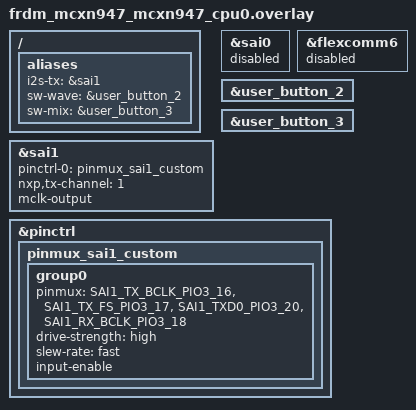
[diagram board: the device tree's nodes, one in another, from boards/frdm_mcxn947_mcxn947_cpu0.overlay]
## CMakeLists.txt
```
# Copyright (c) 2026 Jan-Willem Smaal <usenet@gispen.org>
# SPDX-License-Identifier: Apache-2.0

cmake_minimum_required(VERSION 3.20.0)
set(KCONFIG_ROOT ${CMAKE_CURRENT_SOURCE_DIR}/Kconfig)
find_package(Zephyr REQUIRED HINTS $ENV{ZEPHYR_BASE})
project(mcp4725_sine)

target_sources(app PRIVATE 
    src/main.c 
    src/generators.c
    src/effects.c
    src/mixer.c
)
```

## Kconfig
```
# Copyright (c) 2026 Jan-Willem Smaal <usenet@gispen.org>
# SPDX-License-Identifier: Apache-2.0

menu "Waveform Generator Options"

config WAVEFORM_FREQUENCY
	int "Waveform frequency (Hz)"
	default 1000
	help
	  The target frequency of the generated waveform in Hz.

config AUDIO_SAMPLE_RATE
	int "Sample Rate (Hz)"
	default 192000
	help
	  How many times per second the audio value is updated. (Recommended: 192000 for low aliasing)

config AUDIO_BIT_WIDTH
	int "Sample Bit Width"
	default 16
	range 16 32
	help
	  The bit width of each audio sample (16 or 32).

endmenu

source "Kconfig.zephyr"
```

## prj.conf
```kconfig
CONFIG_GPIO=y
CONFIG_I2S=y
CONFIG_CMSIS_DSP=y
CONFIG_CMSIS_DSP_FASTMATH=y
CONFIG_CMSIS_DSP_BASICMATH=y
CONFIG_I2S_TX_BLOCK_COUNT=8
CONFIG_LOG=y
```

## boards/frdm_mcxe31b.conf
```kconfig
# MCX E-series does not use the i.MX RT style Audio PLL configuration in the SAI driver.
# Disabling this prevents a compilation error in i2s_mcux_sai.c.
CONFIG_I2S_HAS_PLL_SETTING=n
```

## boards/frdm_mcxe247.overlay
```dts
/*
 * FRDM-MCXE247 SAI/I2S Configuration
 * Physical Mapping (Header J1 Inner Row):
 * - Pin 1:  Bit Clock (BCK)   -> PTB8
 * - Pin 5:  Data Out (DIN)    -> PTB9
 * - Pin 11: Frame Sync (LRCK) -> PTE2
 */

&sai1 {
	status = "okay";
	pinctrl-0 = <&pinmux_sai1>;
	pinctrl-names = "default";
	nxp,tx-channel = <1>; /* Bitmask: 1 = Channel 0 (TXD0) */
};

/ {
	aliases {
		i2s-tx = &sai1;
		sw-wave = &user_button_2; /* SW2 */
		sw-mix = &user_button_3;  /* SW3 */
	};
};

&pinctrl {
	pinmux_sai1: pinmux_sai1 {
		group0 {
			pinmux = <SAI1_BCLK_PTB8>,
				 <SAI1_SYNC_PTE2>,
				 <SAI1_D0_PTB9>;
			drive-strength = "high";
			slew-rate = "fast";
			input-enable;
		};
	};
};
```

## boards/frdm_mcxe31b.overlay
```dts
/*
 * FRDM-MCXE31B SAI/I2S Configuration
 * Physical Mapping (Header J1 Inner Row):
 * - Pin 1:  Bit Clock (BCK)   -> PTC12
 * - Pin 5:  Data Out (DIN)    -> PTB2
 * - Pin 11: Frame Sync (LRCK) -> PTC13
 */

&sai_0 {
	status = "okay";
	compatible = "nxp,mcux-i2s";
	pinctrl-0 = <&pinmux_sai0>;
	pinctrl-names = "default";
	#address-cells = <1>;
	#size-cells = <0>;
	#pinmux-cells = <2>;
	clocks = <&mc_cgm 0x2a00>; /* MCUX_SAI0_CLK */
	dmas = <&edma 0 55>, <&edma 0 56>; /* RX, TX */
	dma-names = "rx", "tx";
	nxp,rx-dma-channel = <0>;
	nxp,tx-dma-channel = <1>;
	nxp,tx-channel = <1>; /* Bitmask: 1 = Channel 0 (TXD0) */
};

/ {
	aliases {
		i2s-tx = &sai_0;
		sw-wave = &user_button; /* SW3 on E31B */
	};
};

&pinctrl {
	pinmux_sai0: pinmux_sai0 {
		group0 {
			pinmux = <PTC12_SAI0_BCLK_O>,
				 <PTC13_SAI0_SYNC_O>,
				 <PTB2_SAI0_D0_O>;
			slew-rate = "fastest";
			input-enable;
		};
	};
};
```

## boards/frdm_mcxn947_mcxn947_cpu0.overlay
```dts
&sai1 {
	status = "okay";
	pinctrl-0 = <&pinmux_sai1_custom>;
	pinctrl-names = "default";
	nxp,tx-channel = <1>; /* Bitmask: 1 = Channel 0 (TXD0) */
	mclk-output;          /* MANDATORY for MCXN947 to enable internal clock generator */
};

&sai0 {
	status = "disabled";
};

&flexcomm6 {
	status = "disabled";
};

/ {
	aliases {
		i2s-tx = &sai1;
		sw-wave = &user_button_2; /* SW2 */
		sw-mix = &user_button_3;  /* SW3 */
	};
};

&user_button_2 {
	status = "okay";
};

&user_button_3 {
	status = "okay";
};

&pinctrl {
	pinmux_sai1_custom: pinmux_sai1_custom {
		group0 {
			pinmux = <SAI1_TX_BCLK_PIO3_16>,   /* J1 Pin 1  - Bit Clock */
				 <SAI1_TX_FS_PIO3_17>,     /* J1 Pin 3  - Frame Sync (LRCK) */
				 <SAI1_TXD0_PIO3_20>,      /* J1 Pin 5  - Data Out */
				 <SAI1_RX_BCLK_PIO3_18>;   /* J1 Pin 9  - Bit Clock (Swapped) */
			/* NOTE: PIO1_21 (MCLK) removed to reduce EMI near data lines */
			drive-strength = "high";
			slew-rate = "fast";
			input-enable;
		};
	};
};
```

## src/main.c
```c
/*
 * Copyright 2026 Jan-Willem Smaal <usenet@gispen.org>
 * SPDX-License-Identifier: Apache-2.0
 */

/**
 * @file main.c
 * @brief Multi-Threaded Waveform Generator for PCM5102A (I2S)
 * @author Jan-Willem Smaal <usenet@gispen.org>
 */

#include <zephyr/kernel.h>
#include <zephyr/drivers/i2s.h>
#include <zephyr/drivers/gpio.h>
#include <zephyr/logging/log.h>
#include <arm_math.h>

#include "generators.h"
#include "effects.h"
#include "mixer.h"

LOG_MODULE_REGISTER(waveform_gen, CONFIG_LOG_DEFAULT_LEVEL);

/* --- Configuration --- */
#define I2S_NODE DT_ALIAS(i2s_tx)
#define SW_WAVE_NODE DT_ALIAS(sw_wave)
#define SW_MIX_NODE  DT_ALIAS(sw_mix)

#define SAMPLE_RATE CONFIG_AUDIO_SAMPLE_RATE
#define SAMPLE_BIT_WIDTH CONFIG_AUDIO_BIT_WIDTH
#define CHANNELS 2
#define SAMPLES_PER_BLOCK 128
#define BLOCK_SIZE (SAMPLES_PER_BLOCK * CHANNELS * sizeof(int16_t))
#define BLOCK_COUNT 16

/* Constants for Phase Math */
#define NCO_RANGE_F 4294967296.0f

/* Attenuation factor: ~0.15 (approx -16dB reduction to target -10dBV) */
#define ATTENUATION_FACTOR 4915

/* Audio Thread Settings */
#define AUDIO_STACK_SIZE 2048
#define AUDIO_PRIORITY -2

/* Slab for TX */
K_MEM_SLAB_DEFINE(audio_slab, BLOCK_SIZE, BLOCK_COUNT, 32);
/* Dummy slab for RX */
K_MEM_SLAB_DEFINE(rx_slab, BLOCK_SIZE, 4, 32); 

enum effect_mode {
	EFFECT_BYPASS = 0,
	EFFECT_BITCRUSH,
	EFFECT_BITBEEF,
	EFFECT_COUNT
};

struct synth_state {
	struct k_mutex lock;
	enum waveform_type current_waveform;
	uint32_t frequency;
	uint32_t phase_inc;
	bool mode_changed;
	bool mix_mode;
	enum effect_mode effect;
};

static struct synth_state g_state = {
	.current_waveform = WAVE_SINE,
	.frequency = 440,
	.mode_changed = true,
	.mix_mode = false,
	.effect = EFFECT_BYPASS,
};

static const struct device *const i2s_dev = DEVICE_DT_GET(I2S_NODE);

/* --- Helpers --- */

static void update_phase_inc(struct synth_state *state)
{
	/* Constant for 32-bit phase accumulator: (2^32 / SAMPLE_RATE) */
	const float phase_inc_factor = NCO_RANGE_F / SAMPLE_RATE;
	state->phase_inc = (uint32_t)(state->frequency * phase_inc_factor);
}

static void interleave_stereo(q15_t *mono, int16_t *stereo, uint32_t samples)
{
	for (uint32_t i = 0; i < samples; i++) {
		int16_t val = mono[i];
		stereo[i * 2] = val;     /* Left */
		stereo[i * 2 + 1] = val; /* Right */
	}
}

/* --- Threads --- */

void audio_thread_fn(void *p1, void *p2, void *p3)
{
	struct synth_state *state = (struct synth_state *)p1;
	ARG_UNUSED(p2); ARG_UNUSED(p3);
	uint32_t master_phase = 0;
	q15_t mono_buffer[SAMPLES_PER_BLOCK];
	q15_t mono_buffer2[SAMPLES_PER_BLOCK];
	void *mem_block;
	bool started = false;
	int ret;

	LOG_INF("Audio Engine Thread Started (Priority %d)", AUDIO_PRIORITY);

	while (1) {
		enum waveform_type mode;
		uint32_t phase_inc;
		bool mix_active;
		enum effect_mode effect;
		uint32_t local_phase;

		/* Synchronize control parameters */
		k_mutex_lock(&state->lock, K_FOREVER);
		mode = state->current_waveform;
		phase_inc = state->phase_inc;
		mix_active = state->mix_mode;
		effect = state->effect;

		if (state->mode_changed) {
			const char *fx_name = "BYPASS";

			if (effect == EFFECT_BITCRUSH) {
				fx_name = "BITCRUSH (4-bit)";
			} else if (effect == EFFECT_BITBEEF) {
				fx_name = "BITBEEF (0xBEEF)";
			}

			if (mix_active) {
				LOG_INF("Audio Mode -> %s (Mixed) [Effect: %s]", 
					get_waveform_name(mode), fx_name);
			} else {
				LOG_INF("Audio Mode -> %s [Effect: %s]", 
					get_waveform_name(mode), fx_name);
			}
			state->mode_changed = false;
		}
		k_mutex_unlock(&state->lock);

		/* DSP Pipeline */
		local_phase = master_phase;
		generate_waveform_batch(mode, mono_buffer, SAMPLES_PER_BLOCK, &local_phase, phase_inc);

		if (mix_active) {
			uint32_t harmonic_phase = master_phase * 2;
			uint32_t harmonic_inc = phase_inc * 2;
			uint32_t dummy_phase = harmonic_phase;
			
			generate_waveform_batch(mode, mono_buffer2, SAMPLES_PER_BLOCK, &dummy_phase, harmonic_inc);
			mixer_combine(mono_buffer, mono_buffer2, SAMPLES_PER_BLOCK);
		}

		switch (effect) {
		case EFFECT_BITCRUSH:
			effect_bitcrush(mono_buffer, SAMPLES_PER_BLOCK, 4);
			break;
		case EFFECT_BITBEEF:
			effect_bitbeef(mono_buffer, SAMPLES_PER_BLOCK);
			break;
		default:
			break;
		}

		effect_attenuate(mono_buffer, SAMPLES_PER_BLOCK, ATTENUATION_FACTOR);
		master_phase = local_phase;

		/* Output Processing */
		ret = k_mem_slab_alloc(&audio_slab, &mem_block, K_FOREVER);
		if (ret < 0) {
			continue;
		}

		interleave_stereo(mono_buffer, (int16_t *)mem_block, SAMPLES_PER_BLOCK);

		/* 
		 * Real-time audio: If the queue is full (-EAGAIN), do not block or retry.
		 * The time window has passed, so we simply drop this block and move on.
		 */
		ret = i2s_write(i2s_dev, mem_block, BLOCK_SIZE);
		if (ret < 0) {
			k_mem_slab_free(&audio_slab, mem_block);
			if (ret != -EAGAIN) {
				LOG_ERR("I2S write failed: %d", ret);
				return;
			}
			/* If EAGAIN, we dropped the block. Proceed to next loop immediately. */
			continue;
		}

		if (!started) {
			ret = i2s_trigger(i2s_dev, I2S_DIR_TX, I2S_TRIGGER_START);
			if (ret < 0) {
				LOG_ERR("I2S TX start failed: %d", ret);
				return;
			}
			started = true;
		}
	}
}

/* --- User Interface / Control --- */

void wave_button_pressed(const struct device *dev, struct gpio_callback *cb, uint32_t pins)
{
	ARG_UNUSED(dev); ARG_UNUSED(cb); ARG_UNUSED(pins);

	k_mutex_lock(&g_state.lock, K_NO_WAIT);
	g_state.current_waveform = (g_state.current_waveform + 1) % WAVE_COUNT;
	g_state.mode_changed = true;
	k_mutex_unlock(&g_state.lock);
}

void mix_button_pressed(const struct device *dev, struct gpio_callback *cb, uint32_t pins)
{
	ARG_UNUSED(dev); ARG_UNUSED(cb); ARG_UNUSED(pins);

	k_mutex_lock(&g_state.lock, K_NO_WAIT);
	/* Cycle through effects: BYPASS -> BITCRUSH -> BITBEEF */
	g_state.effect = (g_state.effect + 1) % EFFECT_COUNT;
	g_state.mode_changed = true;
	k_mutex_unlock(&g_state.lock);
}

K_THREAD_DEFINE(audio_tid, AUDIO_STACK_SIZE, audio_thread_fn, &g_state, NULL, NULL,
		AUDIO_PRIORITY, 0, K_TICKS_FOREVER);

int main(void)
{
	struct i2s_config config;
	const struct gpio_dt_spec btn_wave = GPIO_DT_SPEC_GET(SW_WAVE_NODE, gpios);
	struct gpio_callback wave_cb_data;
	int ret;

	/* Mix button is optional (e.g. MCXE31B only has one button) */
	bool has_mix_btn = DT_NODE_EXISTS(SW_MIX_NODE);
	struct gpio_dt_spec btn_mix;
	struct gpio_callback mix_cb_data;

	LOG_INF("Starting Multi-Threaded I2S Audio Engine");
	k_mutex_init(&g_state.lock);
	update_phase_inc(&g_state);

	if (!device_is_ready(i2s_dev)) {
		LOG_ERR("I2S device not ready");
		return -ENODEV;
	}

	/* Configure Hardware ... */

	config.word_size = SAMPLE_BIT_WIDTH;
	config.channels = CHANNELS;
	config.format = I2S_FMT_DATA_FORMAT_I2S;
	config.options = I2S_OPT_FRAME_CLK_CONTROLLER | I2S_OPT_BIT_CLK_CONTROLLER;
	config.frame_clk_freq = SAMPLE_RATE;
	config.block_size = BLOCK_SIZE;
	config.timeout = 2000;

	config.mem_slab = &audio_slab;
	ret = i2s_configure(i2s_dev, I2S_DIR_TX, &config);
	if (ret < 0) {
		LOG_ERR("I2S TX config failed: %d", ret);
		return ret;
	}

	config.mem_slab = &rx_slab;
	ret = i2s_configure(i2s_dev, I2S_DIR_RX, &config);
	if (ret < 0) {
		LOG_ERR("I2S RX config failed: %d", ret);
		return ret;
	}

	/* Initialize UI */
	gpio_pin_configure_dt(&btn_wave, GPIO_INPUT);
	gpio_pin_interrupt_configure_dt(&btn_wave, GPIO_INT_EDGE_TO_ACTIVE);
	gpio_init_callback(&wave_cb_data, wave_button_pressed, BIT(btn_wave.pin));
	
	/* Setup CONTAINER_OF pointer logic for callbacks */
	wave_cb_data.handler = (gpio_callback_handler_t)wave_button_pressed;
	
	gpio_add_callback(btn_wave.port, &wave_cb_data);

	if (has_mix_btn) {
		btn_mix = (struct gpio_dt_spec)GPIO_DT_SPEC_GET(SW_MIX_NODE, gpios);
		gpio_pin_configure_dt(&btn_mix, GPIO_INPUT);
		gpio_pin_interrupt_configure_dt(&btn_mix, GPIO_INT_EDGE_TO_ACTIVE);
		gpio_init_callback(&mix_cb_data, mix_button_pressed, BIT(btn_mix.pin));
		
		/* Setup CONTAINER_OF pointer logic for callbacks */
		mix_cb_data.handler = (gpio_callback_handler_t)mix_button_pressed;
		
		gpio_add_callback(btn_mix.port, &mix_cb_data);
	}

	/* Start Clocks (via RX) */
	ret = i2s_trigger(i2s_dev, I2S_DIR_RX, I2S_TRIGGER_START);
	if (ret < 0) {
		LOG_WRN("I2S RX start failed: %d", ret);
	}

	/* Launch Audio Engine */
	k_thread_start(audio_tid);

	LOG_INF("Control Plane Ready.");
	LOG_INF("SW2: Cycle Waveform Type");
	LOG_INF("SW3: Toggle Bitcrush Effect (A/B Comparison)");

	while (1) {
		k_sleep(K_SECONDS(1));
	}

	return 0;
}
```

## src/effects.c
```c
/**
 * @file effects.c
 * @brief DSP effects implementation
 * @author Jan-Willem Smaal <usenet@gispen.org>
 */

#include "effects.h"


void effect_bitbeef(q15_t *buffer, uint32_t size)
{
	for (uint32_t i = 0; i < size; i++) {
		buffer[i] = (q15_t)(buffer[i] & 0xBEEF);
	}
}

/* This function can be optimized with CMCIS this is the old version */
void effect_bitcrush_old(q15_t *buffer, uint32_t size, uint8_t bits)
{
	if (bits >= 16) {
		return;
	}

	uint16_t mask = 0xFFFF << (16 - bits);

	for (uint32_t i = 0; i < size; i++) {
		buffer[i] = (q15_t)(buffer[i] & mask);
	}
}

void effect_bitcrush(q15_t *buffer, uint32_t size, uint8_t bits)
{
    if (bits >= 16 || bits == 0) {
        return;
    }

	/* For shift right we need a negative number */ 
    int8_t shift_right = (int8_t)(bits - 16); 
	/* For shift left we need positive number */ 
    int8_t shift_left  = (int8_t)(16 - bits); 

    /* Shift to the right we discard precision but we keep the sign bit. */
	arm_shift_q15(buffer, shift_right, buffer, size);

    /* Shift back to the left to restore the amplitude */ 
    arm_shift_q15(buffer, shift_left, buffer, size);
}


void effect_attenuate(q15_t *buffer, uint32_t size, q15_t factor)
{
	arm_scale_q15(buffer, factor, 0, buffer, size);
}
```

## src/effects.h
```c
/**
 * @file effects.h
 * @brief DSP effects for the audio pipeline
 * @author Jan-Willem Smaal <usenet@gispen.org>
 */

#ifndef EFFECTS_H
#define EFFECTS_H

#include <zephyr/kernel.h>
#include <arm_math.h>

/** 
 * @brief Simply AND with 0xBEEF in the buffer. 
 * @param size Number of samples in the buffer.
 */
void effect_bitbeef(q15_t *buffer, uint32_t size);

/**
 * @brief Bitcrushes the buffer in-place to the specified bit depth.
 * 
 * @param buffer The q15_t buffer to process.
 * @param size Number of samples in the buffer.
 * @param bits The bit depth to crush to (e.g., 4, 8, 12, 16). 16 = no crush.
 */
void effect_bitcrush(q15_t *buffer, uint32_t size, uint8_t bits);

/**
 * @brief Applies digital attenuation/volume scaling to the buffer.
 * 
 * @param buffer The q15_t buffer to process.
 * @param size Number of samples in the buffer.
 * @param factor The attenuation factor in Q15 (0..32767).
 */
void effect_attenuate(q15_t *buffer, uint32_t size, q15_t factor);

#endif /* EFFECTS_H */
```

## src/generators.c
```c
/**
 * @file generators.c
 * @brief Waveform generation using Direct Digital Synthesis (DDS)
 * @author Jan-Willem Smaal <usenet@gispen.org>
 * 
 * This implementation is based on the seminal DDS architecture described in:
 * "A Digital Frequency Synthesizer" by J. Tierney, C. M. Rader, and B. Gold (1971).
 * 
 * Phase Modulation (FM) implementation in calc_usr2 is based on:
 * "The Synthesis of Complex Audio Spectra by Means of Frequency Modulation" 
 * by John M. Chowning (1973).
 */

#include "generators.h"

const char *get_waveform_name(enum waveform_type type)
{
	switch (type) {
	case WAVE_SINE:
		return "SINE";
	case WAVE_SQUARE:
		return "SQUARE";
	case WAVE_SAWTOOTH:
		return "SAWTOOTH";
	case WAVE_TRIANGLE:
		return "TRIANGLE";
	case WAVE_USR1:
		return "USR1";
	case WAVE_USR2:
		return "FM SINE";
	default:
		return "UNKNOWN";
	}
}

/**
 * @brief Single Sine point generator
 */
static inline q15_t calc_sine(uint32_t phase)
{
	/* Use top 15 bits for arm_sin_q15 (expects 0..32767) */
	return arm_sin_q15((q15_t)(phase >> 17));
}

/**
 * @brief Single Square point generator
 */
static inline q15_t calc_square(uint32_t phase)
{
	/* MSB determines the half-cycle */
	if (phase < HALF_CYCLE) {
		return Q15_MAX;
	} else {
		return Q15_MIN;
	}
}

/**
 * @brief Single Square point generator with duty cycle.  
 */
static inline q15_t calc_pwm(uint32_t phase, uint32_t amount)
{
	if (phase <= amount) {
		return Q15_MAX;
	} else {
		return Q15_MIN;
	}
}

/**
 * @brief Single Sawtooth point generator
 */
static inline q15_t calc_sawtooth(uint32_t phase)
{
	/* Map 32-bit phase to q15_t range [-32768, 32767] */
	return (q15_t)((phase >> 16) - Q15_MID_OFFSET);
}

/**
 * @brief Single Triangle point generator
 */
static inline q15_t calc_triangle(uint32_t phase)
{
	if (phase < HALF_CYCLE) {
		/* Rising edge: 0..0x7FFFFFFF -> -32768..32767 */
		return (q15_t)((phase >> 15) - Q15_MID_OFFSET);
	} else {
		/* Falling edge: 0x80000000..0xFFFFFFFF -> 32767..-32768 */
		return (q15_t)(Q15_MAX - ((phase - HALF_CYCLE) >> 15));
	}
}

static inline q15_t calc_usr1(uint32_t phase)
{
	/* Simple example pulse wave / specialized ramp */
	return (q15_t)(Q15_MID_OFFSET - (phase >> 16));
}

/**
 * @brief Simple Phase Modulation (FM)
 */
static inline q15_t calc_usr2(uint32_t phase)
{
	/* 2x frequency modulator */
	q15_t mod = arm_sin_q15((q15_t)((phase * 2) >> 17));

	/* Scale modulator for phase offset (modulation index) */
	uint32_t phase_offset = (uint32_t)mod << 14;

	return arm_sin_q15((q15_t)((phase + phase_offset) >> 17));
}

void generate_waveform_batch(enum waveform_type mode, q15_t *buffer, uint32_t size, uint32_t *phase,
			     uint32_t phase_inc)
{
	for (uint32_t i = 0; i < size; i++) {
		switch (mode) {
		case WAVE_SINE:
			buffer[i] = calc_sine(*phase);
			break;
		case WAVE_SQUARE:
			buffer[i] = calc_square(*phase);
			break;
		case WAVE_SAWTOOTH:
			buffer[i] = calc_sawtooth(*phase);
			break;
		case WAVE_TRIANGLE:
			buffer[i] = calc_triangle(*phase);
			break;
		case WAVE_USR1:
			buffer[i] = calc_usr1(*phase);
			break;
		case WAVE_USR2:
			buffer[i] = calc_usr2(*phase);
			break;
		case WAVE_PWM:
			buffer[i] = calc_pwm(*phase, 0xB0000000); 
			break;
		default:
			buffer[i] = 0;
			break;
		}

		*phase += phase_inc;
	}
}
```

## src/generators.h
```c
/**
 * @file generators.h
 * @brief Waveform generator definitions
 * @author Jan-Willem Smaal <usenet@gispen.org>
 */

#ifndef GENERATORS_H
#define GENERATORS_H

#include <zephyr/kernel.h>
#include <arm_math.h>

#define HALF_CYCLE 0x80000000 
#define Q15_MID_OFFSET 32768

/* Waveform selection enum */
enum waveform_type {
	WAVE_SINE = 0,
	WAVE_SQUARE,
	WAVE_SAWTOOTH,
	WAVE_TRIANGLE,
	WAVE_USR1,
	WAVE_USR2, /* FM SINE */
	WAVE_PWM,
	WAVE_COUNT
};

/**
 * @brief Generates a batch of samples for the specified waveform.
 *
 * @param mode The type of waveform to generate.
 * @param buffer Output buffer for raw q15_t samples.
 * @param size Number of samples to generate.
 * @param phase Pointer to the persistent 32-bit phase accumulator.
 * @param phase_inc The 32-bit amount to increment phase per sample.
 */
void generate_waveform_batch(enum waveform_type mode, q15_t *buffer, uint32_t size, uint32_t *phase,
			     uint32_t phase_inc);

/**
 * @brief Returns the human-readable name of a waveform.
 */
const char *get_waveform_name(enum waveform_type type);

#endif /* GENERATORS_H */
```

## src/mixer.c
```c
/*
 * Copyright 2026 Jan-Willem Smaal <usenet@gispen.org>
 * SPDX-License-Identifier: Apache-2.0
 */

/**
 * @file mixer.c
 * @brief Audio mixing implementation
 * @author Jan-Willem Smaal <usenet@gispen.org>
 */

#include "mixer.h"

void mixer_combine(q15_t *dest, q15_t *src, uint32_t size)
{
	arm_scale_q15(dest, 0x4000, 0, dest, size);
	arm_scale_q15(src, 0x4000, 0, src, size);
	arm_add_q15(dest, src, dest, size);
}
```

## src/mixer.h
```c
/**
 * @file mixer.h
 * @brief Audio mixing utilities
 * @author Jan-Willem Smaal <usenet@gispen.org>
 */

#ifndef MIXER_H
#define MIXER_H

#include <zephyr/kernel.h>
#include <arm_math.h>

/**
 * @brief Safely mixes two buffers into the first buffer.
 * Both buffers are scaled by 0.5 before addition to prevent clipping.
 * 
 * @param dest The destination buffer (also the first source).
 * @param src The second source buffer.
 * @param size Number of samples in the buffers.
 */
void mixer_combine(q15_t *dest, q15_t *src, uint32_t size);

#endif /* MIXER_H */
```
